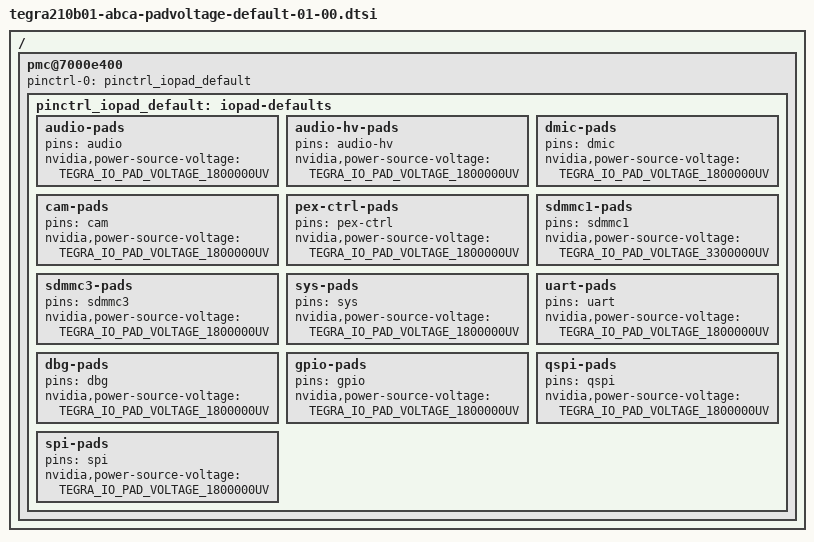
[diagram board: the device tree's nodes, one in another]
/*
 * Copyright (c) 2017, NVIDIA CORPORATION.  All rights reserved.
 *
 * This program is free software; you can redistribute it and/or modify
 * it under the terms of the GNU General Public License as published by
 * the Free Software Foundation; either version 2 of the License, or
 * (at your option) any later version.
 *
 * This program is distributed in the hope that it will be useful, but WITHOUT
 * ANY WARRANTY; without even the implied warranty of MERCHANTABILITY or
 * FITNESS FOR A PARTICULAR PURPOSE.  See the GNU General Public License for
 * more details.
 *
 * You should have received a copy of the GNU General Public License along
 * with this program; if not, write to the Free Software Foundation, Inc.,
 * 51 Franklin Street, Fifth Floor, Boston, MA  02110-1301, USA.
 */

#include <dt-bindings/pinctrl/pinctrl-tegra-io-pad.h>

/ {
	pmc@7000e400 {
		pinctrl-names="default";
		pinctrl-0=<&pinctrl_iopad_default>;
		pinctrl_iopad_default:iopad-defaults {
			audio-pads {
				pins="audio";
				nvidia,power-source-voltage = <TEGRA_IO_PAD_VOLTAGE_1800000UV>;
			};
			audio-hv-pads {
				pins="audio-hv";
				nvidia,power-source-voltage = <TEGRA_IO_PAD_VOLTAGE_1800000UV>;
			};
			dmic-pads {
				pins="dmic";
				nvidia,power-source-voltage = <TEGRA_IO_PAD_VOLTAGE_1800000UV>;
			};
			cam-pads {
				pins="cam";
				nvidia,power-source-voltage = <TEGRA_IO_PAD_VOLTAGE_1800000UV>;
			};
			pex-ctrl-pads {
				pins="pex-ctrl";
				nvidia,power-source-voltage = <TEGRA_IO_PAD_VOLTAGE_1800000UV>;
			};
			sdmmc1-pads {
				pins="sdmmc1";
				nvidia,power-source-voltage = <TEGRA_IO_PAD_VOLTAGE_3300000UV>;
			};
			sdmmc3-pads {
				pins="sdmmc3";
				nvidia,power-source-voltage = <TEGRA_IO_PAD_VOLTAGE_1800000UV>;
			};
			sys-pads {
				pins="sys";
				nvidia,power-source-voltage = <TEGRA_IO_PAD_VOLTAGE_1800000UV>;
			};
			uart-pads {
				pins="uart";
				nvidia,power-source-voltage = <TEGRA_IO_PAD_VOLTAGE_1800000UV>;
			};
			dbg-pads {
				pins="dbg";
				nvidia,power-source-voltage = <TEGRA_IO_PAD_VOLTAGE_1800000UV>;
			};
			gpio-pads {
				pins="gpio";
				nvidia,power-source-voltage = <TEGRA_IO_PAD_VOLTAGE_1800000UV>;
			};
			qspi-pads {
				pins="qspi";
				nvidia,power-source-voltage = <TEGRA_IO_PAD_VOLTAGE_1800000UV>;
			};
			spi-pads {
				pins="spi";
				nvidia,power-source-voltage = <TEGRA_IO_PAD_VOLTAGE_1800000UV>;
			};
		};
	};
};
